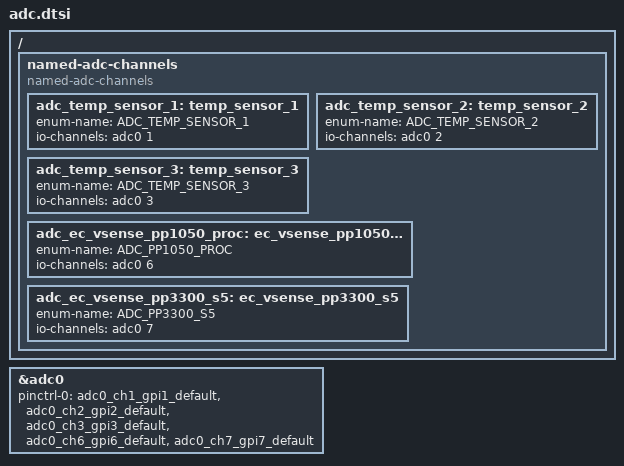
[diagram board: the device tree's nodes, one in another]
/* Copyright 2025 The ChromiumOS Authors
 * Use of this source code is governed by a BSD-style license that can be
 * found in the LICENSE file.
 */

/{
        named-adc-channels {
		compatible = "named-adc-channels";

		adc_temp_sensor_1: temp_sensor_1 {
			enum-name = "ADC_TEMP_SENSOR_1";
			io-channels = <&adc0 1>;
		};
		adc_temp_sensor_2: temp_sensor_2 {
			enum-name = "ADC_TEMP_SENSOR_2";
			io-channels = <&adc0 2>;
		};
		adc_temp_sensor_3: temp_sensor_3 {
			enum-name = "ADC_TEMP_SENSOR_3";
			io-channels = <&adc0 3>;
		};
		adc_ec_vsense_pp1050_proc: ec_vsense_pp1050_proc {
			enum-name = "ADC_PP1050_PROC";
			io-channels = <&adc0 6>;
		};
		adc_ec_vsense_pp3300_s5: ec_vsense_pp3300_s5 {
			enum-name = "ADC_PP3300_S5";
			io-channels = <&adc0 7>;
		};
	};
};

&adc0 {
	pinctrl-0 = <&adc0_ch1_gpi1_default
		     &adc0_ch2_gpi2_default
		     &adc0_ch3_gpi3_default
		     &adc0_ch6_gpi6_default
		     &adc0_ch7_gpi7_default>;
	pinctrl-names = "default";
	status = "okay";
};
